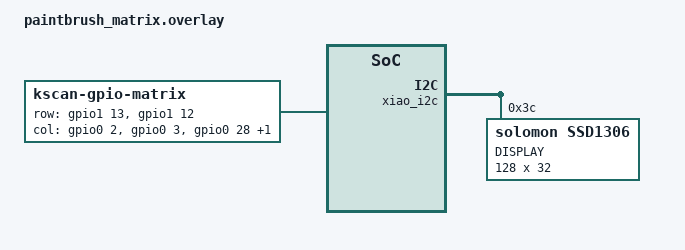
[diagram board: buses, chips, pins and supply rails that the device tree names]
/*
 * Copyright (c) 2020 Ryan Cross
 *
 * SPDX-License-Identifier: MIT
 */

/ {
    chosen {
        zmk,kscan = &kscan0;
    };

    kscan0: kscan {
        compatible = "zmk,kscan-gpio-matrix";
        label = "KSCAN";

        diode-direction = "col2row";
        row-gpios
            = <&gpio1 13 (GPIO_ACTIVE_HIGH | GPIO_PULL_DOWN)>
            , <&gpio1 12 (GPIO_ACTIVE_HIGH | GPIO_PULL_DOWN)>
            ;
    };
};

&kscan0 {
	col-gpios
		= <&gpio0 2 GPIO_ACTIVE_HIGH>
		, <&gpio0 3 GPIO_ACTIVE_HIGH>
		, <&gpio0 28 GPIO_ACTIVE_HIGH>
		, <&gpio0 29 GPIO_ACTIVE_HIGH>
		;
};


&xiao_i2c {
	status = "okay";
	oled: ssd1306@3c {
		compatible = "solomon,ssd1306";
		reg = <0x3c>;
		label = "DISPLAY";
		width = <128>;
		height = <32>;
		segment-offset = <0>;
		page-offset = <0>;
		display-offset = <0>;
		multiplex-ratio = <31>;
		segment-remap;
		com-invdir;
		com-sequential;
		prechargep = <0x22>;
	};
